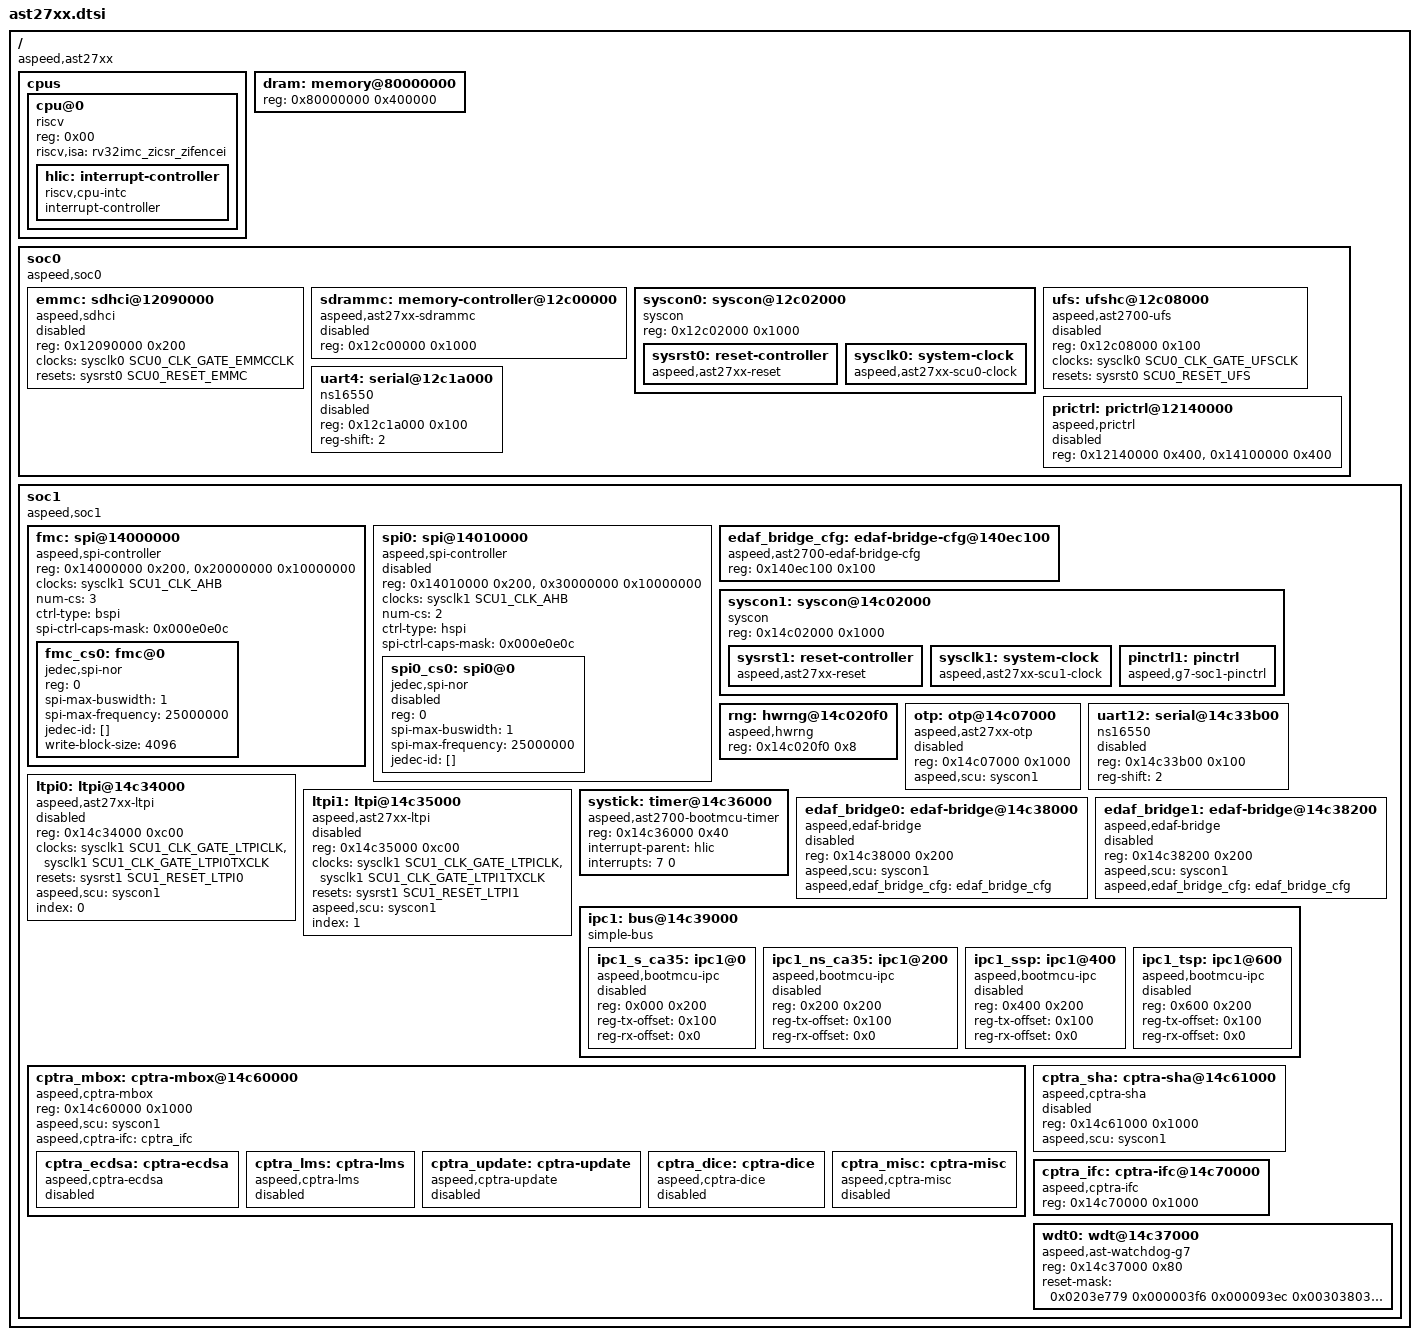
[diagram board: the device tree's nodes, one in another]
/*
 * Copyright (c) 2024 Aspeed Technology Inc.
 *
 * SPDX-License-Identifier: Apache-2.0
 */

#include <zephyr/dt-bindings/clock/ast27xx_clock.h>
#include <zephyr/dt-bindings/misc/ast27xx_prictrl.h>
#include <zephyr/dt-bindings/reset/ast27xx_reset.h>
#include <zephyr/dt-bindings/pinctrl/ast27xx-soc1-pinctrl-groups.h>
/ {
	#address-cells = <0x01>;
	#size-cells = <0x01>;
	compatible = "aspeed,ast27xx";

	cpus {
		#address-cells = <0x01>;
		#size-cells = <0x00>;

		cpu@0 {
			device_type = "cpu";
			reg = <0x00>;
			status = "okay";
			compatible = "riscv";
			riscv,isa = "rv32imc_zicsr_zifencei";

			hlic: interrupt-controller {
				compatible = "riscv,cpu-intc";
				#address-cells = <0>;
				#interrupt-cells = <1>;
				interrupt-controller;
			};
		};
	};

	dram: memory@80000000 {
		reg = <0x80000000 0x400000>;
	};

	soc0 {
		compatible = "aspeed,soc0", "simple-bus";
		#address-cells = <0x01>;
		#size-cells = <0x01>;
		ranges;

		emmc: sdhci@12090000 {
			compatible = "aspeed,sdhci";
			reg = <0x12090000 0x200>;
			clocks = <&sysclk0 SCU0_CLK_GATE_EMMCCLK>;
			resets = <&sysrst0 SCU0_RESET_EMMC>;
			status = "disabled";
		};

		sdrammc: memory-controller@12c00000 {
			compatible = "aspeed,ast27xx-sdrammc";
			reg = <0x12c00000 0x1000>;
			status = "disabled";
		};

		syscon0: syscon@12c02000 {
			compatible = "syscon";
			reg = <0x12c02000 0x1000>;

			sysrst0: reset-controller {
				compatible = "aspeed,ast27xx-reset";
				#reset-cells = <1>;
			};

			sysclk0: system-clock {
				compatible = "aspeed,ast27xx-scu0-clock";
				#clock-cells = <1>;
			};
		};

		ufs: ufshc@12c08000 {
			compatible = "aspeed,ast2700-ufs";
			reg = <0x12c08000 0x100>;
			clocks = <&sysclk0 SCU0_CLK_GATE_UFSCLK>;
			resets = <&sysrst0 SCU0_RESET_UFS>;
			status = "disabled";
		};

		uart4: serial@12c1a000 {
			compatible = "ns16550";
			reg = <0x12c1a000 0x100>;
			reg-shift = <2>;
			status = "disabled";
		};

		prictrl: prictrl@12140000{
			compatible = "aspeed,prictrl";
			reg = <0x12140000 0x400>, <0x14100000 0x400>;
			reg-names = "cpu", "io";
			status = "disabled";
		};
	};

	soc1 {
		compatible = "aspeed,soc1", "simple-bus";
		#address-cells = <0x01>;
		#size-cells = <0x01>;
		ranges;

		fmc: spi@14000000 {
			compatible = "aspeed,spi-controller";
			reg = <0x14000000 0x200>, <0x20000000 0x10000000>;
			reg-names = "ctrl_reg", "spi_mmap";
			clocks = <&sysclk1 SCU1_CLK_AHB>;
			num-cs = <3>;
			ctrl-type = "bspi";
			#address-cells = <1>;
			#size-cells = <0>;
			spi-ctrl-caps-mask = <0x000e0e0c>;

			fmc_cs0: fmc@0 {
				compatible = "jedec,spi-nor";
				reg = <0>;
				spi-max-buswidth = <1>;
				spi-max-frequency = <25000000>;
				jedec-id = [];
				write-block-size = <4096>;
			};
		};

		spi0: spi@14010000 {
			compatible = "aspeed,spi-controller";
			reg = <0x14010000 0x200>, <0x30000000 0x10000000>;
			reg-names = "ctrl_reg", "spi_mmap";
			clocks = <&sysclk1 SCU1_CLK_AHB>;
			num-cs = <2>;
			ctrl-type = "hspi";
			#address-cells = <1>;
			#size-cells = <0>;
			spi-ctrl-caps-mask = <0x000e0e0c>;
			status = "disabled";

			spi0_cs0: spi0@0 {
				compatible = "jedec,spi-nor";
				reg = <0>;
				spi-max-buswidth = <1>;
				spi-max-frequency = <25000000>;
				jedec-id = [];
				status = "disabled";
			};
		};

		edaf_bridge_cfg: edaf-bridge-cfg@140ec100 {
			compatible = "aspeed,ast2700-edaf-bridge-cfg";
			reg = <0x140ec100 0x100>;
		};

		syscon1: syscon@14c02000 {
			compatible = "syscon";
			reg = <0x14c02000 0x1000>;

			sysrst1: reset-controller {
				compatible = "aspeed,ast27xx-reset";
				#reset-cells = <1>;
			};

			sysclk1: system-clock {
				compatible = "aspeed,ast27xx-scu1-clock";
				#clock-cells = <1>;
			};

			pinctrl1: pinctrl {
				compatible = "aspeed,g7-soc1-pinctrl";
			};
		};

		rng: hwrng@14c020f0 {
			compatible = "aspeed,hwrng";
			reg = <0x14c020f0 0x8>;
		};

		otp: otp@14c07000 {
			compatible = "aspeed,ast27xx-otp";
			reg = <0x14c07000 0x1000>;
			aspeed,scu = <&syscon1>;
			status = "disabled";
		};

		uart12: serial@14c33b00 {
			compatible = "ns16550";
			reg = <0x14c33b00 0x100>;
			reg-shift = <2>;
			status = "disabled";
		};

		ltpi0: ltpi@14c34000 {
			compatible = "aspeed,ast27xx-ltpi";
			reg = <0x14c34000 0xc00>;
			clocks = <&sysclk1 SCU1_CLK_GATE_LTPICLK>,
				 <&sysclk1 SCU1_CLK_GATE_LTPI0TXCLK>;
			clock-names = "ahb", "phy";
			resets = <&sysrst1 SCU1_RESET_LTPI0>;
			aspeed,scu = <&syscon1>;
			index = <0>;
			status = "disabled";
		};

		ltpi1: ltpi@14c35000 {
			compatible = "aspeed,ast27xx-ltpi";
			reg = <0x14c35000 0xc00>;
			clocks = <&sysclk1 SCU1_CLK_GATE_LTPICLK>,
				 <&sysclk1 SCU1_CLK_GATE_LTPI1TXCLK>;
			clock-names = "ahb", "phy";
			resets = <&sysrst1 SCU1_RESET_LTPI1>;
			aspeed,scu = <&syscon1>;
			index = <1>;
			status = "disabled";
		};

		systick: timer@14c36000 {
			compatible = "aspeed,ast2700-bootmcu-timer";
			reg = <0x14c36000 0x40>;
			interrupt-parent = <&hlic>;
			interrupts = <7 0>;
		};

		edaf_bridge0: edaf-bridge@14c38000 {
			compatible = "aspeed,edaf-bridge";
			reg = <0x14c38000 0x200>;
			aspeed,scu = <&syscon1>;
			aspeed,edaf_bridge_cfg= <&edaf_bridge_cfg>;
			status = "disabled";
		};

		edaf_bridge1: edaf-bridge@14c38200 {
			compatible = "aspeed,edaf-bridge";
			reg = <0x14c38200 0x200>;
			aspeed,scu = <&syscon1>;
			aspeed,edaf_bridge_cfg= <&edaf_bridge_cfg>;
			status = "disabled";
		};

		ipc1: bus@14c39000 {
			#address-cells = <1>;
			#size-cells = <1>;
			compatible = "simple-bus";
			ranges = <0 0x14c39000 0x1000>;

			ipc1_s_ca35: ipc1@0 {
				compatible = "aspeed,bootmcu-ipc";
				reg = <0x000 0x200>;
				reg-tx-offset = <0x100>;
				reg-rx-offset = <0x0>;
				status = "disabled";
			};

			ipc1_ns_ca35: ipc1@200 {
				compatible = "aspeed,bootmcu-ipc";
				reg = <0x200 0x200>;
				reg-tx-offset = <0x100>;
				reg-rx-offset = <0x0>;
				status = "disabled";
			};

			ipc1_ssp: ipc1@400 {
				compatible = "aspeed,bootmcu-ipc";
				reg = <0x400 0x200>;
				reg-tx-offset = <0x100>;
				reg-rx-offset = <0x0>;
				status = "disabled";
			};

			ipc1_tsp: ipc1@600 {
				compatible = "aspeed,bootmcu-ipc";
				reg = <0x600 0x200>;
				reg-tx-offset = <0x100>;
				reg-rx-offset = <0x0>;
				status = "disabled";
			};
		};

		cptra_mbox: cptra-mbox@14c60000 {
			compatible = "aspeed,cptra-mbox";
			reg = <0x14c60000 0x1000>;
			aspeed,scu = <&syscon1>;
			aspeed,cptra-ifc = <&cptra_ifc>;

			cptra_ecdsa: cptra-ecdsa {
				compatible = "aspeed,cptra-ecdsa";
				status = "disabled";
			};

			cptra_lms: cptra-lms {
				compatible = "aspeed,cptra-lms";
				status = "disabled";
			};

			cptra_update: cptra-update {
				compatible = "aspeed,cptra-update";
				status = "disabled";
			};

			cptra_dice: cptra-dice {
				compatible = "aspeed,cptra-dice";
				status = "disabled";
			};

			cptra_misc: cptra-misc {
				compatible = "aspeed,cptra-misc";
				status = "disabled";
			};
		};

		cptra_sha: cptra-sha@14c61000 {
			compatible = "aspeed,cptra-sha";
			reg = <0x14c61000 0x1000>;
			aspeed,scu = <&syscon1>;
			status = "disabled";
		};

		cptra_ifc: cptra-ifc@14c70000 {
			compatible = "aspeed,cptra-ifc";
			reg = <0x14c70000 0x1000>;
		};

		wdt0: wdt@14c37000 {
			compatible = "aspeed,ast-watchdog-g7";
			reg = <0x14c37000 0x80>;
			reset-mask= <0x0203e779 0x000003f6 0x000093ec 0x00303803 0x00020000>;
		};
	};
};

#include "ast27xx-pinctrl.dtsi"
